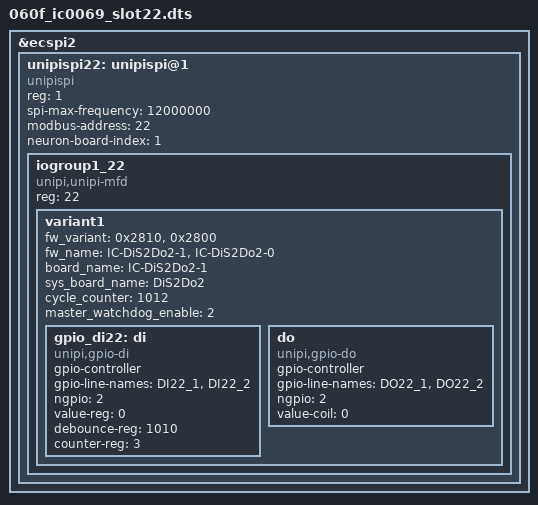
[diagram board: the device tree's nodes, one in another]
/dts-v1/;


/plugin/;

/ {
	fragment@1 {
		
		target = <&ecspi2>;
		__overlay__ {
			status = "okay";
			#address-cells = <1>;
			#size-cells = <0>;

			unipispi22: unipispi@1 {
				compatible = "unipispi";
				reg = <1>;
				status = "okay";
				spi-max-frequency = <12000000>;
				modbus-address = <22>;
				neuron-board-index = <1>;
			};
		};

	};

	fragment@2 {
		target = <&unipispi22>;
		__overlay__ {
			#address-cells = <1>;
			#size-cells = <0>;

			iogroup1_22 {
				reg = <22>;
				compatible = "unipi,unipi-mfd", "iogroup";
				variant1 { 
					fw_variant = <0x2810>, <0x2800>;
					fw_name = "IC-DiS2Do2-1" , "IC-DiS2Do2-0";
					board_name = "IC-DiS2Do2-1";
					sys_board_name = "DiS2Do2";
					cycle_counter = <1012>;
					master_watchdog_enable = <2>;

					gpio_di22:di {
						compatible = "unipi,gpio-di";
						gpio-controller;
						#gpio-cells = <2>;
						gpio-line-names = "DI22_1", "DI22_2";
						ngpio = <2>;
						value-reg = <0>;
						debounce-reg = <1010>;
						counter-reg = <3>;
					};
					do {
						compatible = "unipi,gpio-do";
						gpio-controller;
						#gpio-cells = <2>;
						gpio-line-names = "DO22_1", "DO22_2";
						ngpio = <2>;
						value-coil = <0>;
					};
				};
			};
		};
	};
};
